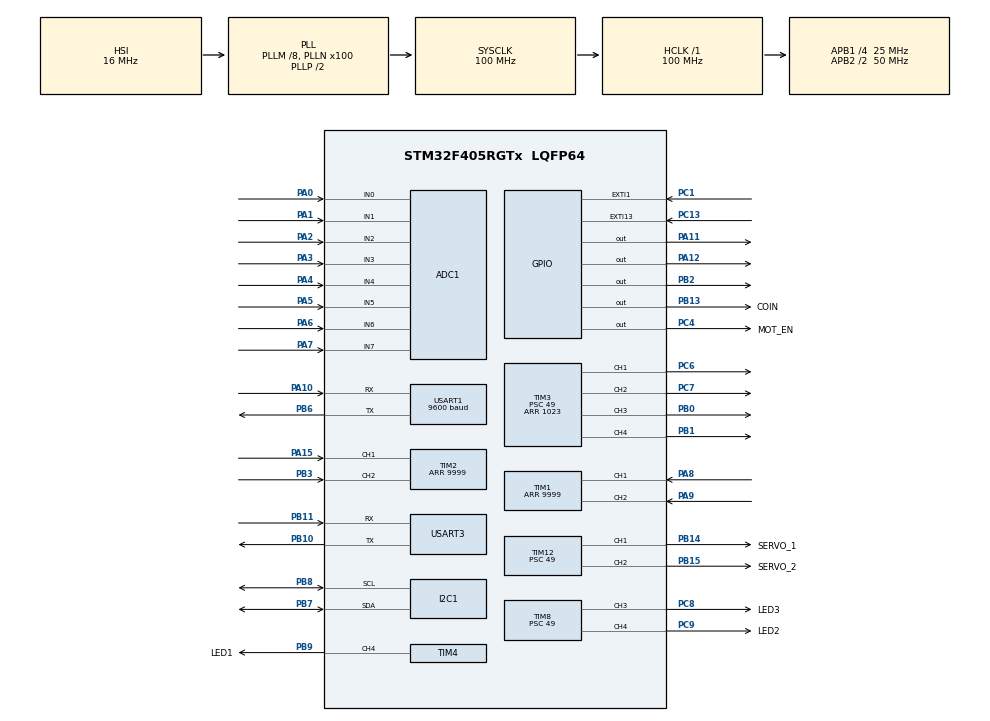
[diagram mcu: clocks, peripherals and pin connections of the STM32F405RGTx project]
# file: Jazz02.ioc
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ADC1.Channel-0\#ChannelRegularConversion=ADC_CHANNEL_0
ADC1.NbrOfConversionFlag=1
ADC1.Rank-0\#ChannelRegularConversion=1
ADC1.SamplingTime-0\#ChannelRegularConversion=ADC_SAMPLETIME_3CYCLES
ADC1.master=1
Mcu.Family=STM32F4
Mcu.Name=STM32F405RGTx
Mcu.Package=LQFP64
NVIC.EXTI15_10_IRQn=true\:0\:0\:false\:false\:true\:true\:true\:true
NVIC.EXTI1_IRQn=true\:0\:0\:false\:false\:true\:true\:true\:true
NVIC.PriorityGroup=NVIC_PRIORITYGROUP_4
NVIC.USART1_IRQn=true\:0\:0\:false\:false\:true\:true\:true\:true
NVIC.USART3_IRQn=true\:0\:0\:false\:false\:true\:true\:true\:true
PA0-WKUP.Signal=ADCx_IN0
PA1.Signal=ADCx_IN1
PA10.Mode=Asynchronous
PA10.Signal=USART1_RX
PA11.Signal=GPIO_Output
PA12.Signal=GPIO_Output
PA15.Signal=S_TIM2_CH1_ETR
PA2.Signal=ADCx_IN2
PA3.Signal=ADCx_IN3
PA4.Signal=ADCx_IN4
PA5.Signal=ADCx_IN5
PA6.Signal=ADCx_IN6
PA7.Signal=ADCx_IN7
PA8.Signal=S_TIM1_CH1
PA9.Signal=S_TIM1_CH2
PB0.Signal=S_TIM3_CH3
PB1.Signal=S_TIM3_CH4
PB10.Mode=Asynchronous
PB10.Signal=USART3_TX
PB11.Mode=Asynchronous
PB11.Signal=USART3_RX
PB13.GPIO_Label=COIN
PB13.PinState=GPIO_PIN_RESET
PB13.Signal=GPIO_Output
PB14.GPIO_Label=SERVO_1
PB14.Signal=S_TIM12_CH1
PB15.GPIO_Label=SERVO_2
PB15.Signal=S_TIM12_CH2
PB2.Signal=GPIO_Output
PB3.Signal=S_TIM2_CH2
PB6.Mode=Asynchronous
PB6.Signal=USART1_TX
PB7.Mode=I2C
PB7.Signal=I2C1_SDA
PB8.Mode=I2C
PB8.Signal=I2C1_SCL
PB9.GPIO_Label=LED1
PB9.Signal=S_TIM4_CH4
PC1.GPIO_ModeDefaultEXTI=GPIO_MODE_IT_FALLING
PC1.GPIO_PuPd=GPIO_PULLUP
PC1.Signal=GPXTI1
PC13-ANTI_TAMP.GPIO_ModeDefaultEXTI=GPIO_MODE_IT_FALLING
PC13-ANTI_TAMP.GPIO_PuPd=GPIO_PULLUP
PC13-ANTI_TAMP.Signal=GPXTI13
PC4.GPIO_Label=MOT_EN
PC4.Signal=GPIO_Output
PC6.Signal=S_TIM3_CH1
PC7.Signal=S_TIM3_CH2
PC8.GPIO_Label=LED3
PC8.Signal=S_TIM8_CH3
PC9.GPIO_Label=LED2
PC9.Signal=S_TIM8_CH4
ProjectManager.HeapSize=0x200
ProjectManager.StackSize=0x400
ProjectManager.TargetToolchain=CMake
RCC.48MHZClocksFreq_Value=50000000
RCC.AHBFreq_Value=100000000
RCC.APB1CLKDivider=RCC_HCLK_DIV4
RCC.APB1Freq_Value=25000000
RCC.APB1TimFreq_Value=50000000
RCC.APB2CLKDivider=RCC_HCLK_DIV2
RCC.APB2Freq_Value=50000000
RCC.APB2TimFreq_Value=100000000
RCC.CortexFreq_Value=100000000
RCC.HCLKFreq_Value=100000000
RCC.HSE_VALUE=25000000
RCC.HSI_VALUE=16000000
RCC.LSE_VALUE=32768
RCC.PLLM=8
RCC.PLLN=100
RCC.SYSCLKFreq_VALUE=100000000
RCC.SYSCLKSource=RCC_SYSCLKSOURCE_PLLCLK
RCC.VCOOutputFreq_Value=200000000
SH.ADCx_IN0.0=ADC1_IN0,IN0
SH.ADCx_IN1.0=ADC1_IN1,IN1
SH.ADCx_IN2.0=ADC1_IN2,IN2
SH.ADCx_IN3.0=ADC1_IN3,IN3
SH.ADCx_IN4.0=ADC1_IN4,IN4
SH.ADCx_IN5.0=ADC1_IN5,IN5
SH.ADCx_IN6.0=ADC1_IN6,IN6
SH.ADCx_IN7.0=ADC1_IN7,IN7
SH.S_TIM12_CH1.0=TIM12_CH1,PWM Generation1 CH1
SH.S_TIM12_CH2.0=TIM12_CH2,PWM Generation2 CH2
SH.S_TIM1_CH1.0=TIM1_CH1,Encoder_Interface
SH.S_TIM1_CH2.0=TIM1_CH2,Encoder_Interface
SH.S_TIM2_CH1_ETR.0=TIM2_CH1,Encoder_Interface
SH.S_TIM2_CH2.0=TIM2_CH2,Encoder_Interface
SH.S_TIM3_CH1.0=TIM3_CH1,PWM Generation1 CH1
SH.S_TIM3_CH2.0=TIM3_CH2,PWM Generation2 CH2
SH.S_TIM3_CH3.0=TIM3_CH3,PWM Generation3 CH3
SH.S_TIM3_CH4.0=TIM3_CH4,PWM Generation4 CH4
SH.S_TIM4_CH4.0=TIM4_CH4,PWM Generation4 CH4
SH.S_TIM8_CH3.0=TIM8_CH3,PWM Generation3 CH3
SH.S_TIM8_CH4.0=TIM8_CH4,PWM Generation4 CH4
TIM1.CounterMode=TIM_COUNTERMODE_UP
TIM1.EncoderMode=TIM_ENCODERMODE_TI12
TIM1.Period=9999
TIM12.AutoReloadPreload=TIM_AUTORELOAD_PRELOAD_DISABLE
TIM12.Channel-PWM\ Generation1\ CH1=TIM_CHANNEL_1
TIM12.Channel-PWM\ Generation2\ CH2=TIM_CHANNEL_2
TIM12.Period=20000
TIM12.Prescaler=49
TIM12.Pulse-PWM\ Generation1\ CH1=0
TIM2.CounterMode=TIM_COUNTERMODE_UP
TIM2.EncoderMode=TIM_ENCODERMODE_TI12
TIM2.Period=9999
TIM3.Channel-PWM\ Generation1\ CH1=TIM_CHANNEL_1
TIM3.Channel-PWM\ Generation2\ CH2=TIM_CHANNEL_2
TIM3.Channel-PWM\ Generation3\ CH3=TIM_CHANNEL_3
TIM3.Channel-PWM\ Generation4\ CH4=TIM_CHANNEL_4
TIM3.Period=1023
TIM3.Prescaler=49
TIM4.Channel-PWM\ Generation4\ CH4=TIM_CHANNEL_4
TIM4.Period=100
TIM4.Prescaler=49
TIM6.Prescaler=99
TIM8.Channel-PWM\ Generation3\ CH3=TIM_CHANNEL_3
TIM8.Channel-PWM\ Generation4\ CH4=TIM_CHANNEL_4
TIM8.Period=100
TIM8.Prescaler=49
USART1.BaudRate=9600
USART1.VirtualMode=VM_ASYNC
USART3.VirtualMode=VM_ASYNC
VP_TIM6_VS_ClockSourceINT.Mode=Enable_Timer
board=custom

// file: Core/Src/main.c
/* USER CODE BEGIN Header */
/**
 ******************************************************************************
 * @file           : main.c
 * @brief          : Main program body
 ******************************************************************************
 * @attention
 *
 * Copyright (c) 2024 STMicroelectronics.
 * All rights reserved.
 *
 * This software is licensed under terms that can be found in the LICENSE file
 * in the root directory of this software component.
 * If no LICENSE file comes with this software, it is provided AS-IS.
 *
 ******************************************************************************
 */
/* USER CODE END Header */
#include "main.h"
#include "adc.h"
#include "i2c.h"
#include "tim.h"
#include "usart.h"
#include "gpio.h"

/* USER CODE BEGIN Includes */
#include "loop.h"
/* USER CODE END Includes */

void SystemClock_Config(void);
/* USER CODE BEGIN PFP */

void _write(int file, char *ptr, int len)
{
  HAL_UART_Transmit(&huart1, (uint8_t *)ptr, len, 1000);
}

/* USER CODE END PFP */

int main(void)
{

  /* MCU Configuration--------------------------------------------------------*/

  /* Reset of all peripherals, Initializes the Flash interface and the Systick. */
  HAL_Init();

  /* Configure the system clock */
  SystemClock_Config();

  /* Initialize all configured peripherals */
  MX_GPIO_Init();
  MX_ADC1_Init();
  MX_I2C1_Init();
  MX_TIM1_Init();
  MX_TIM2_Init();
  MX_TIM3_Init();
  MX_TIM6_Init();
  MX_USART1_UART_Init();
  MX_USART3_UART_Init();
  MX_TIM4_Init();
  MX_TIM8_Init();
  MX_TIM12_Init();
  /* USER CODE BEGIN 2 */

  setup();

  /* USER CODE END 2 */

  /* Infinite loop */
  /* USER CODE BEGIN WHILE */
  while (1)
  {
    loop();
    /* USER CODE END WHILE */

  }
}

void SystemClock_Config(void)
{
  RCC_OscInitTypeDef RCC_OscInitStruct = {0};
  RCC_ClkInitTypeDef RCC_ClkInitStruct = {0};

  /** Configure the main internal regulator output voltage
  */
  __HAL_RCC_PWR_CLK_ENABLE();
  __HAL_PWR_VOLTAGESCALING_CONFIG(PWR_REGULATOR_VOLTAGE_SCALE1);

  /** Initializes the RCC Oscillators according to the specified parameters
  * in the RCC_OscInitTypeDef structure.
  */
  RCC_OscInitStruct.OscillatorType = RCC_OSCILLATORTYPE_HSI;
  RCC_OscInitStruct.HSIState = RCC_HSI_ON;
  RCC_OscInitStruct.HSICalibrationValue = RCC_HSICALIBRATION_DEFAULT;
  RCC_OscInitStruct.PLL.PLLState = RCC_PLL_ON;
  RCC_OscInitStruct.PLL.PLLSource = RCC_PLLSOURCE_HSI;
  RCC_OscInitStruct.PLL.PLLM = 8;
  RCC_OscInitStruct.PLL.PLLN = 100;
  RCC_OscInitStruct.PLL.PLLP = RCC_PLLP_DIV2;
  RCC_OscInitStruct.PLL.PLLQ = 4;
  if (HAL_RCC_OscConfig(&RCC_OscInitStruct) != HAL_OK)
  {
    Error_Handler();
  }

  /** Initializes the CPU, AHB and APB buses clocks
  */
  RCC_ClkInitStruct.ClockType = RCC_CLOCKTYPE_HCLK|RCC_CLOCKTYPE_SYSCLK
                              |RCC_CLOCKTYPE_PCLK1|RCC_CLOCKTYPE_PCLK2;
  RCC_ClkInitStruct.SYSCLKSource = RCC_SYSCLKSOURCE_PLLCLK;
  RCC_ClkInitStruct.AHBCLKDivider = RCC_SYSCLK_DIV1;
  RCC_ClkInitStruct.APB1CLKDivider = RCC_HCLK_DIV4;
  RCC_ClkInitStruct.APB2CLKDivider = RCC_HCLK_DIV2;

  if (HAL_RCC_ClockConfig(&RCC_ClkInitStruct, FLASH_LATENCY_3) != HAL_OK)
  {
    Error_Handler();
  }
}

void Error_Handler(void)
{
  __disable_irq();
  while (1)
  {
  }
}
